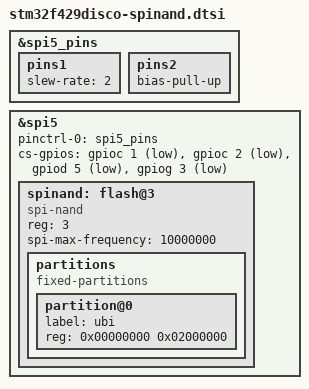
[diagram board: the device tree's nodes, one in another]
/*
 * Winbond W25N02KV sharing SPI5 with the onboard devices and W5500.
 *
 * P2 pin 6 / PF7: SPI5 clock
 * P2 pin 5 / PF8: SPI5 MISO (flash DO/IO1)
 * P2 pin 8 / PF9: SPI5 MOSI (flash DI/IO0)
 * P2 pin 61 / PG3: flash chip select
 *
 * The chip is 256 MiB. Only its first 32 MiB are intentionally exposed so
 * this initial integration has a small, fixed UBI wear-leveling domain.
 */

/* Override the onboard-only SPI5 electrical defaults for external wiring. */
&spi5_pins {
	pins1 {
		slew-rate = <2>;
	};

	pins2 {
		bias-pull-up;
	};
};

&spi5 {
	status = "okay";
	pinctrl-names = "default";
	pinctrl-0 = <&spi5_pins>;
	/* CS0: gyroscope; CS1: LCD; CS2: W5500; CS3: SPI-NAND. */
	cs-gpios = <&gpioc 1 GPIO_ACTIVE_LOW>,
		     <&gpioc 2 GPIO_ACTIVE_LOW>,
		     <&gpiod 5 GPIO_ACTIVE_LOW>,
		     <&gpiog 3 GPIO_ACTIVE_LOW>;

	spinand: flash@3 {
		compatible = "spi-nand";
		reg = <3>;
		spi-max-frequency = <10000000>;

		partitions {
			compatible = "fixed-partitions";
			#address-cells = <1>;
			#size-cells = <1>;

			partition@0 {
				label = "ubi";
				reg = <0x00000000 0x02000000>;
			};
		};
	};
};
